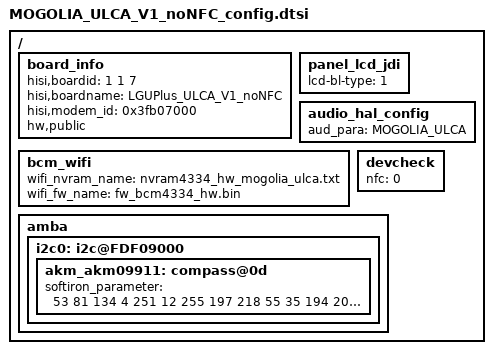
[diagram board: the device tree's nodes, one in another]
/*
 * Hisilicon Ltd.
 *
 * A15x4 A7x4
 *
 * It is only a demo for hisilicon hi3630 board. You show change the
 * address of each node according to datasheet.
 */


/include/ "huawei-sensor.dtsi"

/include/ "MOGOLIA_TL_V1_config.dtsi"
/include/ "hisi_3630_modem_MOGOLIA_ULCA_V1_noNFC.dtsi"
/include/ "hisi_3630_pin_MOGOLIA_ULCA_V1_noNFC.dtsi"
/ {
	board_info: board_info {
		hisi,boardid = <1 1 7>;
		hisi,boardname = "LGUPlus_ULCA_V1_noNFC";
		hisi,modem_id = <0x3fb07000>;
		hw,public;
	};

	panel_lcd_jdi {
		lcd-bl-type = <1>;
	};

	audio_hal_config {
		aud_para = "MOGOLIA_ULCA";
	};

	bcm_wifi {
		wifi_nvram_name = "nvram4334_hw_mogolia_ulca.txt";
		wifi_fw_name = "fw_bcm4334_hw.bin";
		status = "ok";
	};

	devcheck: devcheck {
		nfc = <0>;
	};
	amba{
    i2c0: i2c@FDF09000{
        akm_akm09911:compass@0d{
           softiron_parameter = <53 81 134 4 251 12 255 197 218 55 35 194 201 129 255 167 255 5 20 151 197 252 226 116 11 197 91>;
            };
	    };	
    };
};
